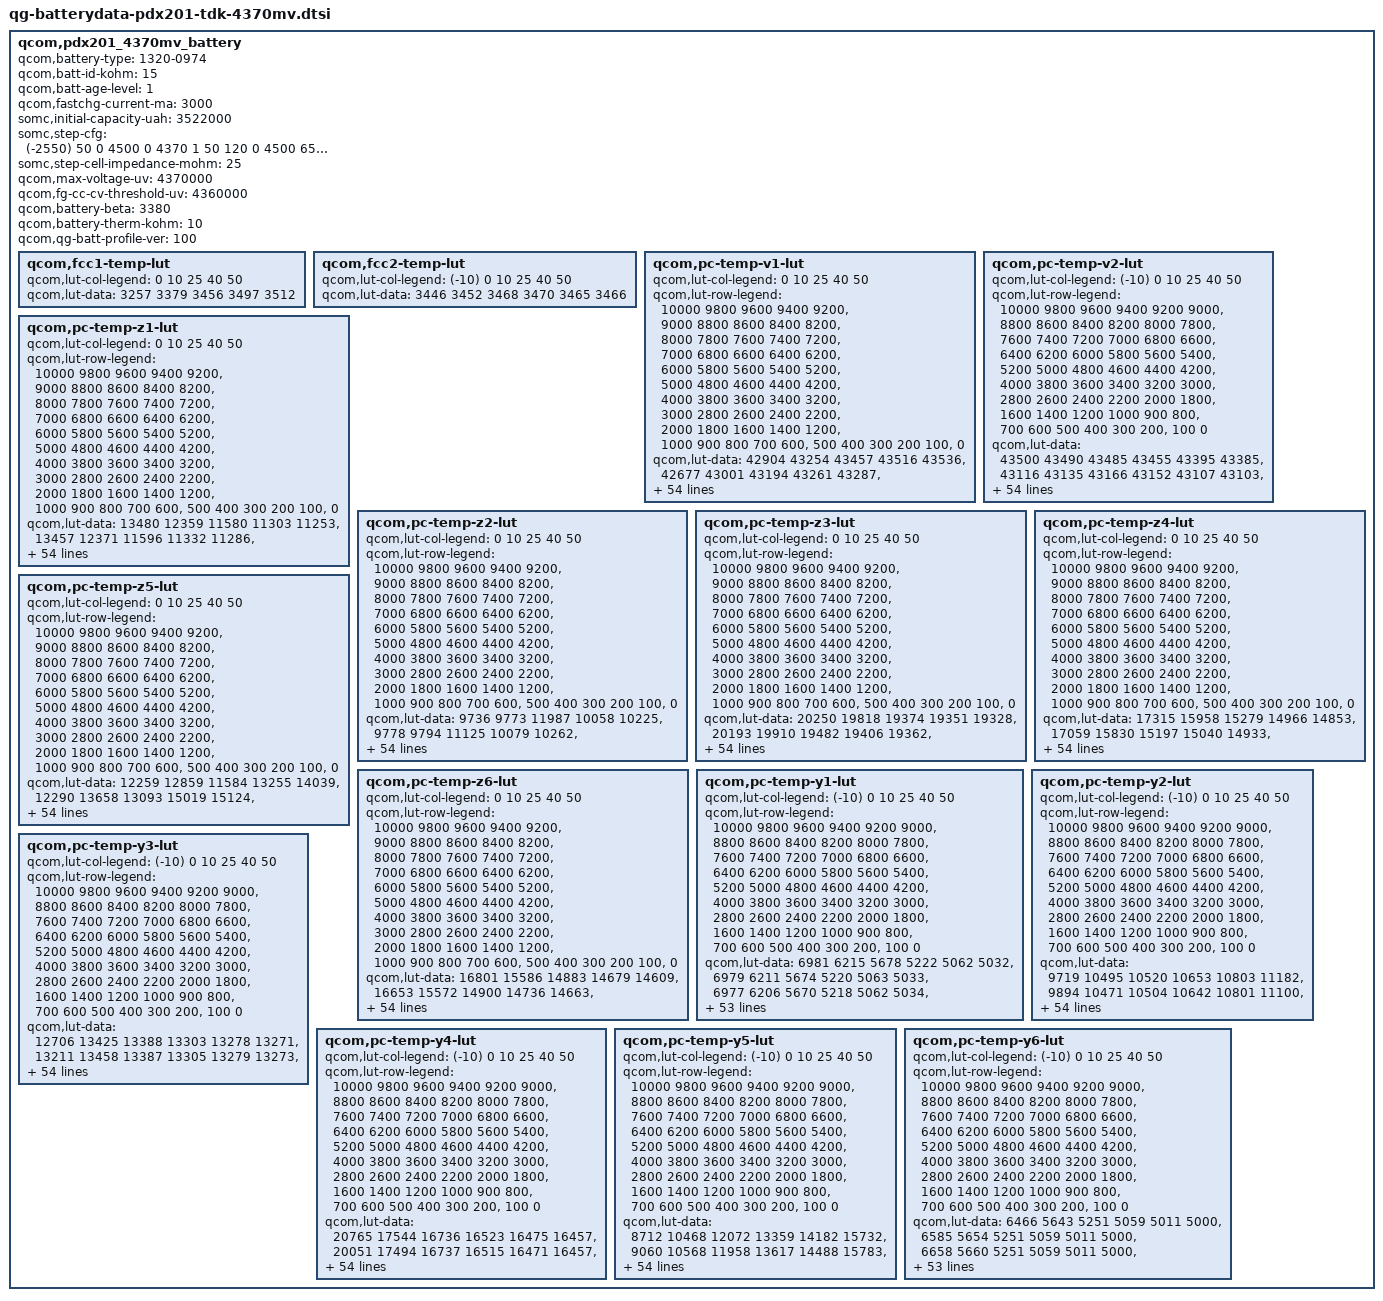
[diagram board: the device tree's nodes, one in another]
// SPDX-License-Identifier: GPL-2.0-only
/*
 * Copyright (c) 2019, The Linux Foundation. All rights reserved.
 */

qcom,pdx201_4370mv_battery {
	/* Added or Modified by SOMC */
	qcom,battery-type = "1320-0974";
	qcom,batt-id-kohm = <15>;
	qcom,batt-age-level = <1>;
	qcom,fastchg-current-ma = <3000>;
	somc,initial-capacity-uah = <3522000>;
	somc,step-cfg = <
		(-2550) 50    0 4500    0 4370 1
		   50  120    0 4500  650 4370 2
		  120  200    0 4100 2050 4370 3
		  120  200 4100 4200 1550 4370 3
		  120  200 4200 4300 1350 4370 3
		  120  200 4300 4500 1000 4370 3
		  200  450    0 4150 3000 4370 3
		  200  450 4150 4200 2400 4370 3
		  200  450 4200 4300 1700 4370 3
		  200  450 4300 4500 1000 4370 3
		  450  550    0 4500 1000 4200 4
		  550 2550    0 4500    0 4200 5
	>;
	somc,step-cell-impedance-mohm = <25>;

	/* Prepared by Qualcomm */
	/* 4209985_SoMC_Amuro2_3471mAh_averaged_MasterSlave_Oct15th2019 */
	qcom,max-voltage-uv = <4370000>;
	qcom,fg-cc-cv-threshold-uv = <4360000>;
	/* qcom,fastchg-current-ma = <1500>; */
	/* qcom,batt-id-kohm = <330>; */
	qcom,battery-beta = <3380>;
	qcom,battery-therm-kohm = <10>;
	/* qcom,battery-type = "4209985_SoMC_Amuro2_3471mAh_averaged_MasterSlave_Oct15th2019"; */
	qcom,qg-batt-profile-ver = <100>;

	qcom,fcc1-temp-lut {
		qcom,lut-col-legend = <0 10 25 40 50>;
		qcom,lut-data = <3257 3379 3456 3497 3512>;
	};

	qcom,fcc2-temp-lut {
		qcom,lut-col-legend = <(-10) 0 10 25 40 50>;
		qcom,lut-data = <3446 3452 3468 3470 3465 3466>;
	};

	qcom,pc-temp-v1-lut {
		qcom,lut-col-legend = <0 10 25 40 50>;
		qcom,lut-row-legend = <10000 9800 9600 9400 9200>,
			<9000 8800 8600 8400 8200>,
			<8000 7800 7600 7400 7200>,
			<7000 6800 6600 6400 6200>,
			<6000 5800 5600 5400 5200>,
			<5000 4800 4600 4400 4200>,
			<4000 3800 3600 3400 3200>,
			<3000 2800 2600 2400 2200>,
			<2000 1800 1600 1400 1200>,
			<1000 900 800 700 600>,
			<500 400 300 200 100>,
			<0>;
		qcom,lut-data = <42904 43254 43457 43516 43536>,
			<42677 43001 43194 43261 43287>,
			<42458 42763 42939 43014 43038>,
			<42249 42536 42696 42775 42796>,
			<42047 42315 42463 42543 42564>,
			<41847 42103 42235 42315 42338>,
			<41641 41895 42011 42087 42114>,
			<41447 41687 41793 41862 41892>,
			<41289 41475 41578 41642 41673>,
			<41164 41289 41365 41423 41454>,
			<41010 41154 41178 41212 41237>,
			<40723 41025 41035 41024 41028>,
			<40349 40810 40889 40855 40826>,
			<40089 40440 40652 40665 40629>,
			<39930 40121 40309 40421 40432>,
			<39804 39959 40059 40181 40242>,
			<39691 39839 39936 40009 40065>,
			<39594 39723 39835 39873 39901>,
			<39496 39618 39710 39732 39741>,
			<39382 39508 39568 39589 39592>,
			<39262 39376 39406 39433 39440>,
			<39146 39227 39196 39227 39250>,
			<39032 39063 38977 38981 39020>,
			<38920 38856 38802 38799 38832>,
			<38810 38664 38648 38677 38699>,
			<38698 38547 38533 38574 38585>,
			<38596 38461 38455 38478 38479>,
			<38505 38395 38392 38389 38381>,
			<38423 38342 38329 38307 38293>,
			<38363 38298 38266 38229 38214>,
			<38320 38257 38209 38160 38143>,
			<38285 38220 38156 38100 38077>,
			<38254 38187 38108 38048 38019>,
			<38227 38157 38067 38000 37966>,
			<38203 38131 38035 37961 37923>,
			<38179 38102 38000 37921 37878>,
			<38157 38075 37966 37876 37818>,
			<38122 38040 37928 37827 37748>,
			<38062 37980 37871 37764 37673>,
			<37983 37891 37784 37680 37598>,
			<37890 37793 37682 37581 37513>,
			<37774 37685 37572 37472 37407>,
			<37641 37560 37446 37346 37281>,
			<37489 37408 37295 37195 37127>,
			<37362 37268 37160 37060 36993>,
			<37279 37189 37075 36975 36913>,
			<37257 37163 37053 36954 36892>,
			<37238 37146 37041 36942 36877>,
			<37212 37130 37022 36923 36857>,
			<37132 37068 36961 36851 36773>,
			<36849 36802 36688 36562 36471>,
			<36406 36363 36261 36130 36038>,
			<35840 35798 35701 35569 35477>,
			<35078 35035 34944 34807 34713>,
			<33876 33848 33780 33634 33539>,
			<30000 30000 30000 30000 30000>;
	};

	qcom,pc-temp-v2-lut {
		qcom,lut-col-legend = <(-10) 0 10 25 40 50>;
		qcom,lut-row-legend = <10000 9800 9600 9400 9200 9000>,
			<8800 8600 8400 8200 8000 7800>,
			<7600 7400 7200 7000 6800 6600>,
			<6400 6200 6000 5800 5600 5400>,
			<5200 5000 4800 4600 4400 4200>,
			<4000 3800 3600 3400 3200 3000>,
			<2800 2600 2400 2200 2000 1800>,
			<1600 1400 1200 1000 900 800>,
			<700 600 500 400 300 200>,
			<100 0>;
		qcom,lut-data = <43500 43490 43485 43455 43395 43385>,
			<43116 43135 43166 43152 43107 43103>,
			<42779 42815 42874 42872 42838 42837>,
			<42501 42538 42612 42616 42587 42588>,
			<42276 42297 42378 42383 42356 42357>,
			<42051 42070 42154 42159 42131 42132>,
			<41765 41846 41933 41936 41906 41907>,
			<41483 41630 41719 41717 41686 41686>,
			<41332 41417 41504 41497 41468 41469>,
			<41260 41203 41285 41274 41252 41255>,
			<41169 41011 41088 41071 41044 41045>,
			<40912 40869 40941 40913 40856 40841>,
			<40515 40739 40802 40764 40674 40642>,
			<40172 40524 40582 40547 40468 40449>,
			<39849 40137 40230 40226 40230 40259>,
			<39598 39791 39925 39966 40019 40078>,
			<39462 39605 39749 39833 39869 39909>,
			<39362 39463 39608 39729 39739 39747>,
			<39229 39313 39449 39591 39591 39584>,
			<39055 39160 39274 39422 39430 39425>,
			<38851 39009 39104 39239 39255 39255>,
			<38568 38858 38938 39029 39042 39045>,
			<38251 38711 38779 38818 38821 38826>,
			<38108 38586 38642 38659 38657 38662>,
			<38057 38484 38523 38537 38533 38536>,
			<38019 38377 38415 38429 38425 38426>,
			<37976 38217 38317 38330 38326 38326>,
			<37936 38039 38228 38241 38236 38235>,
			<37897 37946 38149 38160 38155 38151>,
			<37860 37904 38077 38086 38080 38075>,
			<37823 37871 38009 38018 38013 38006>,
			<37783 37838 37931 37954 37951 37943>,
			<37741 37807 37858 37895 37894 37885>,
			<37701 37772 37805 37837 37832 37821>,
			<37661 37731 37767 37782 37769 37753>,
			<37621 37688 37729 37726 37698 37674>,
			<37579 37645 37686 37662 37611 37571>,
			<37536 37603 37640 37595 37515 37457>,
			<37481 37550 37584 37526 37433 37367>,
			<37407 37484 37518 37457 37365 37297>,
			<37323 37407 37440 37379 37291 37223>,
			<37240 37315 37342 37282 37197 37130>,
			<37154 37204 37227 37167 37084 37020>,
			<37073 37078 37089 37024 36940 36876>,
			<36995 36960 36969 36919 36846 36787>,
			<36919 36884 36905 36877 36811 36753>,
			<36879 36855 36886 36862 36796 36738>,
			<36828 36821 36864 36840 36775 36716>,
			<36759 36770 36831 36802 36731 36675>,
			<36645 36663 36744 36684 36596 36524>,
			<36394 36420 36468 36338 36250 36164>,
			<35969 35983 36001 35863 35766 35671>,
			<35362 35383 35397 35243 35130 35039>,
			<34502 34559 34582 34389 34264 34162>,
			<33256 33381 33402 33070 32960 32838>,
			<29559 29540 29526 29587 29522 29522>;
	};

	qcom,pc-temp-z1-lut {
		qcom,lut-col-legend = <0 10 25 40 50>;
		qcom,lut-row-legend = <10000 9800 9600 9400 9200>,
			<9000 8800 8600 8400 8200>,
			<8000 7800 7600 7400 7200>,
			<7000 6800 6600 6400 6200>,
			<6000 5800 5600 5400 5200>,
			<5000 4800 4600 4400 4200>,
			<4000 3800 3600 3400 3200>,
			<3000 2800 2600 2400 2200>,
			<2000 1800 1600 1400 1200>,
			<1000 900 800 700 600>,
			<500 400 300 200 100>,
			<0>;
		qcom,lut-data = <13480 12359 11580 11303 11253>,
			<13457 12371 11596 11332 11286>,
			<13452 12376 11605 11341 11297>,
			<13471 12378 11605 11345 11303>,
			<13498 12378 11603 11348 11306>,
			<13511 12378 11603 11350 11309>,
			<13510 12377 11604 11351 11309>,
			<13506 12376 11605 11351 11309>,
			<13506 12375 11607 11351 11309>,
			<13500 12376 11609 11352 11309>,
			<13490 12380 11610 11353 11310>,
			<13466 12385 11609 11355 11310>,
			<13433 12381 11609 11357 11311>,
			<13415 12354 11604 11358 11312>,
			<13407 12334 11592 11354 11312>,
			<13401 12333 11586 11350 11313>,
			<13396 12333 11591 11351 11314>,
			<13390 12336 11598 11355 11315>,
			<13386 12348 11604 11358 11316>,
			<13396 12363 11608 11359 11317>,
			<13417 12372 11611 11360 11318>,
			<13426 12380 11614 11361 11319>,
			<13425 12384 11615 11362 11320>,
			<13423 12387 11618 11363 11321>,
			<13424 12389 11621 11364 11322>,
			<13426 12393 11624 11366 11324>,
			<13428 12398 11628 11369 11326>,
			<13430 12403 11632 11372 11328>,
			<13432 12409 11636 11375 11330>,
			<13434 12415 11639 11377 11332>,
			<13437 12421 11643 11379 11334>,
			<13439 12431 11646 11381 11336>,
			<13444 12437 11649 11383 11337>,
			<13451 12437 11652 11384 11338>,
			<13457 12436 11655 11386 11339>,
			<13460 12439 11659 11387 11340>,
			<13462 12445 11662 11389 11341>,
			<13467 12451 11665 11390 11342>,
			<13479 12459 11668 11391 11342>,
			<13495 12468 11670 11391 11343>,
			<13509 12471 11672 11392 11343>,
			<13523 12468 11674 11393 11344>,
			<13527 12466 11676 11394 11345>,
			<13530 12471 11678 11395 11345>,
			<13467 12471 11682 11396 11346>,
			<13436 12466 11682 11397 11346>,
			<13443 12461 11682 11396 11346>,
			<13449 12456 11682 11395 11346>,
			<13449 12469 11682 11396 11346>,
			<13453 12459 11684 11396 11346>,
			<13451 12477 11691 11398 11348>,
			<13469 12488 11701 11405 11352>,
			<13503 12522 11718 11412 11359>,
			<13522 12561 11743 11425 11368>,
			<13522 12561 11743 11425 11368>,
			<13522 12561 11743 11425 11368>;
	};

	qcom,pc-temp-z2-lut {
		qcom,lut-col-legend = <0 10 25 40 50>;
		qcom,lut-row-legend = <10000 9800 9600 9400 9200>,
			<9000 8800 8600 8400 8200>,
			<8000 7800 7600 7400 7200>,
			<7000 6800 6600 6400 6200>,
			<6000 5800 5600 5400 5200>,
			<5000 4800 4600 4400 4200>,
			<4000 3800 3600 3400 3200>,
			<3000 2800 2600 2400 2200>,
			<2000 1800 1600 1400 1200>,
			<1000 900 800 700 600>,
			<500 400 300 200 100>,
			<0>;
		qcom,lut-data = <9736 9773 11987 10058 10225>,
			<9778 9794 11125 10079 10262>,
			<9806 9797 10550 10278 10486>,
			<9821 9798 10353 10384 10664>,
			<9832 9799 10304 10361 10654>,
			<9838 9809 10301 10333 10616>,
			<9841 9821 10180 10335 10550>,
			<9843 9826 10041 10356 10390>,
			<9842 9828 10113 10364 10287>,
			<9835 9831 10377 10258 10297>,
			<9827 9856 10503 10133 10319>,
			<9818 9888 10478 10125 10340>,
			<9809 9890 10447 10140 10366>,
			<9806 9866 10466 10154 10379>,
			<9807 9849 10548 10165 10378>,
			<9809 9858 10586 10177 10378>,
			<9812 9882 10368 10196 10383>,
			<9817 9907 10095 10221 10407>,
			<9820 9934 10075 10233 10425>,
			<9818 9961 10130 10233 10430>,
			<9815 9979 10174 10233 10434>,
			<9814 9994 10198 10286 10432>,
			<9820 10010 10215 10411 10427>,
			<9828 10035 10213 10450 10425>,
			<9837 10054 10202 10352 10456>,
			<9848 10052 10195 10259 10499>,
			<9857 10041 10207 10282 10516>,
			<9865 10033 10225 10350 10514>,
			<9872 10030 10237 10376 10494>,
			<9874 10029 10250 10374 10395>,
			<9873 10030 10256 10370 10300>,
			<9873 10035 10245 10364 10296>,
			<9874 10041 10231 10358 10306>,
			<9876 10045 10230 10363 10321>,
			<9880 10049 10238 10394 10363>,
			<9885 10053 10248 10433 10429>,
			<9891 10057 10262 10466 10551>,
			<9899 10062 10280 10501 10718>,
			<9910 10072 10300 10532 10759>,
			<9923 10086 10324 10571 10679>,
			<9936 10095 10338 10594 10609>,
			<9950 10099 10342 10581 10604>,
			<9972 10105 10346 10559 10603>,
			<10015 10124 10352 10524 10603>,
			<10239 10245 10405 10529 10627>,
			<10239 10286 10436 10542 10650>,
			<10232 10277 10411 10515 10634>,
			<10229 10273 10408 10524 10644>,
			<10239 10285 10411 10536 10694>,
			<10267 10314 10456 10670 10767>,
			<10273 10335 10478 10584 10506>,
			<10212 10283 10417 10496 10390>,
			<10122 10245 10365 10417 10363>,
			<9934 10194 10290 10353 10300>,
			<9934 10194 10290 10353 10300>,
			<9934 10194 10290 10353 10300>;
	};

	qcom,pc-temp-z3-lut {
		qcom,lut-col-legend = <0 10 25 40 50>;
		qcom,lut-row-legend = <10000 9800 9600 9400 9200>,
			<9000 8800 8600 8400 8200>,
			<8000 7800 7600 7400 7200>,
			<7000 6800 6600 6400 6200>,
			<6000 5800 5600 5400 5200>,
			<5000 4800 4600 4400 4200>,
			<4000 3800 3600 3400 3200>,
			<3000 2800 2600 2400 2200>,
			<2000 1800 1600 1400 1200>,
			<1000 900 800 700 600>,
			<500 400 300 200 100>,
			<0>;
		qcom,lut-data = <20250 19818 19374 19351 19328>,
			<20193 19910 19482 19406 19362>,
			<20131 19914 19556 19430 19395>,
			<20054 19907 19583 19438 19413>,
			<19974 19898 19601 19439 19411>,
			<19935 19877 19607 19439 19407>,
			<19923 19854 19579 19438 19400>,
			<19914 19841 19547 19430 19383>,
			<19902 19830 19551 19419 19369>,
			<19887 19826 19575 19404 19366>,
			<19879 19844 19587 19388 19364>,
			<19900 19870 19573 19377 19359>,
			<19943 19866 19555 19368 19351>,
			<19957 19814 19550 19366 19345>,
			<19931 19757 19550 19367 19342>,
			<19902 19714 19546 19369 19340>,
			<19895 19677 19485 19368 19336>,
			<19893 19656 19412 19362 19331>,
			<19892 19642 19408 19360 19327>,
			<19912 19635 19428 19361 19327>,
			<19949 19642 19451 19362 19326>,
			<19966 19665 19485 19370 19329>,
			<19970 19692 19515 19387 19338>,
			<19973 19731 19517 19392 19343>,
			<19980 19763 19509 19374 19333>,
			<19995 19763 19499 19356 19321>,
			<20005 19751 19485 19358 19330>,
			<20006 19738 19472 19368 19361>,
			<20006 19722 19472 19380 19375>,
			<20003 19707 19482 19401 19372>,
			<19989 19698 19491 19416 19368>,
			<19971 19691 19503 19414 19365>,
			<19959 19687 19513 19409 19363>,
			<19951 19684 19513 19403 19360>,
			<19942 19681 19505 19396 19354>,
			<19932 19679 19497 19390 19349>,
			<19920 19676 19492 19388 19352>,
			<19911 19674 19488 19387 19359>,
			<19905 19672 19483 19385 19361>,
			<19898 19670 19478 19382 19357>,
			<19885 19667 19475 19378 19352>,
			<19865 19659 19474 19376 19346>,
			<19842 19648 19473 19374 19341>,
			<19808 19628 19462 19363 19343>,
			<19673 19576 19438 19356 19339>,
			<19668 19546 19427 19354 19329>,
			<19663 19547 19427 19353 19328>,
			<19655 19542 19412 19342 19326>,
			<19642 19527 19414 19340 19322>,
			<19629 19525 19404 19333 19323>,
			<19631 19515 19395 19339 19345>,
			<19626 19519 19393 19346 19348>,
			<19588 19511 19396 19355 19350>,
			<19501 19478 19384 19358 19356>,
			<19501 19478 19384 19358 19356>,
			<19501 19478 19384 19358 19356>;
	};

	qcom,pc-temp-z4-lut {
		qcom,lut-col-legend = <0 10 25 40 50>;
		qcom,lut-row-legend = <10000 9800 9600 9400 9200>,
			<9000 8800 8600 8400 8200>,
			<8000 7800 7600 7400 7200>,
			<7000 6800 6600 6400 6200>,
			<6000 5800 5600 5400 5200>,
			<5000 4800 4600 4400 4200>,
			<4000 3800 3600 3400 3200>,
			<3000 2800 2600 2400 2200>,
			<2000 1800 1600 1400 1200>,
			<1000 900 800 700 600>,
			<500 400 300 200 100>,
			<0>;
		qcom,lut-data = <17315 15958 15279 14966 14853>,
			<17059 15830 15197 15040 14933>,
			<16831 15669 15119 14980 14897>,
			<16630 15485 15039 14922 14854>,
			<16449 15344 14949 14882 14818>,
			<16287 15247 14900 14849 14787>,
			<16144 15169 14882 14824 14781>,
			<16011 15109 14864 14802 14781>,
			<15878 15063 14833 14795 14781>,
			<15743 15006 14778 14795 14775>,
			<15636 14882 14737 14796 14762>,
			<15569 14754 14710 14792 14752>,
			<15517 14748 14692 14776 14745>,
			<15457 14842 14692 14764 14737>,
			<15383 14911 14698 14758 14728>,
			<15309 14909 14708 14752 14717>,
			<15248 14902 14747 14739 14708>,
			<15196 14894 14791 14718 14698>,
			<15148 14883 14787 14703 14691>,
			<15096 14872 14754 14695 14685>,
			<15048 14859 14736 14690 14681>,
			<15026 14846 14760 14719 14701>,
			<15015 14843 14802 14802 14778>,
			<15010 14882 14842 14850 14827>,
			<15010 14929 14888 14869 14844>,
			<15011 14945 14909 14879 14853>,
			<15013 14953 14904 14870 14839>,
			<15021 14956 14893 14842 14788>,
			<15034 14954 14877 14811 14753>,
			<15040 14949 14849 14770 14737>,
			<15043 14942 14822 14737 14724>,
			<15044 14931 14794 14722 14711>,
			<15043 14920 14771 14713 14698>,
			<15037 14909 14764 14709 14693>,
			<15029 14899 14762 14707 14692>,
			<15021 14893 14761 14707 14691>,
			<15012 14888 14763 14711 14700>,
			<15005 14885 14768 14722 14721>,
			<14999 14890 14777 14733 14727>,
			<14995 14902 14797 14745 14727>,
			<14993 14905 14808 14753 14727>,
			<14993 14899 14800 14748 14724>,
			<14986 14889 14792 14742 14719>,
			<14953 14878 14794 14754 14722>,
			<14867 14821 14776 14748 14720>,
			<14852 14797 14745 14721 14708>,
			<14846 14787 14735 14707 14692>,
			<14839 14783 14731 14695 14670>,
			<14830 14780 14715 14681 14656>,
			<14829 14774 14728 14698 14671>,
			<14843 14799 14764 14718 14667>,
			<14865 14800 14768 14711 14665>,
			<14900 14804 14764 14701 14663>,
			<14985 14824 14771 14694 14655>,
			<14985 14824 14771 14694 14655>,
			<14985 14824 14771 14694 14655>;
	};

	qcom,pc-temp-z5-lut {
		qcom,lut-col-legend = <0 10 25 40 50>;
		qcom,lut-row-legend = <10000 9800 9600 9400 9200>,
			<9000 8800 8600 8400 8200>,
			<8000 7800 7600 7400 7200>,
			<7000 6800 6600 6400 6200>,
			<6000 5800 5600 5400 5200>,
			<5000 4800 4600 4400 4200>,
			<4000 3800 3600 3400 3200>,
			<3000 2800 2600 2400 2200>,
			<2000 1800 1600 1400 1200>,
			<1000 900 800 700 600>,
			<500 400 300 200 100>,
			<0>;
		qcom,lut-data = <12259 12859 11584 13255 14039>,
			<12290 13658 13093 15019 15124>,
			<12314 14011 14431 15808 16926>,
			<12329 14225 15645 16253 18176>,
			<12349 14396 16820 16491 18562>,
			<12379 14524 17405 16675 18791>,
			<12478 14657 17095 16953 18643>,
			<12599 14870 16744 17310 17405>,
			<12668 15205 17650 17439 16524>,
			<12708 15789 20126 16673 16683>,
			<12767 19308 22234 15721 16949>,
			<13041 23872 23704 15512 16946>,
			<13485 24148 24798 15433 16649>,
			<13664 20720 25192 15419 16462>,
			<13672 17644 24965 15670 16707>,
			<13675 16476 24122 16119 17104>,
			<13740 15690 19588 16640 17269>,
			<13960 15537 14496 17349 17342>,
			<14307 15743 14192 18167 17463>,
			<15192 16134 15890 19033 18058>,
			<16644 17119 18636 20220 19015>,
			<17856 19388 28981 23194 20082>,
			<18715 22650 40479 28069 21476>,
			<19612 30174 40170 29325 21966>,
			<21002 36946 32397 23069 18633>,
			<23048 36303 25644 16766 14766>,
			<24654 31552 21402 15870 14868>,
			<25544 27375 18462 15492 16367>,
			<26213 24572 18016 15576 17404>,
			<26301 22443 18154 17717 17878>,
			<25124 21584 18503 20446 18408>,
			<23659 21098 20734 22351 19598>,
			<22982 20900 23672 24028 21575>,
			<22547 20990 24529 25104 22955>,
			<22249 21205 24851 25903 23720>,
			<22025 21447 24963 26309 24391>,
			<21859 21773 24729 25971 25312>,
			<21873 22087 24206 25036 26268>,
			<22573 22333 23324 23832 26239>,
			<23305 22545 21574 21362 23198>,
			<23207 22574 20601 19417 20000>,
			<22661 22059 20641 19026 18784>,
			<22727 21514 20675 18696 17981>,
			<23595 21096 19244 16773 17385>,
			<24541 22814 19204 16424 16634>,
			<24783 22104 19982 17292 16145>,
			<24052 22565 20065 17800 16750>,
			<23399 22238 18542 17114 18163>,
			<22815 20914 19806 18056 19559>,
			<22186 21464 18377 16195 17232>,
			<22385 19108 15692 14669 18022>,
			<18785 18284 15136 14945 18460>,
			<15876 16975 15029 15595 18532>,
			<13323 14722 14127 15877 20298>,
			<13323 14722 14127 15877 20298>,
			<13323 14722 14127 15877 20298>;
	};

	qcom,pc-temp-z6-lut {
		qcom,lut-col-legend = <0 10 25 40 50>;
		qcom,lut-row-legend = <10000 9800 9600 9400 9200>,
			<9000 8800 8600 8400 8200>,
			<8000 7800 7600 7400 7200>,
			<7000 6800 6600 6400 6200>,
			<6000 5800 5600 5400 5200>,
			<5000 4800 4600 4400 4200>,
			<4000 3800 3600 3400 3200>,
			<3000 2800 2600 2400 2200>,
			<2000 1800 1600 1400 1200>,
			<1000 900 800 700 600>,
			<500 400 300 200 100>,
			<0>;
		qcom,lut-data = <16801 15586 14883 14679 14609>,
			<16653 15572 14900 14736 14663>,
			<16516 15525 14906 14727 14664>,
			<16384 15433 14899 14716 14663>,
			<16261 15356 14870 14703 14655>,
			<16165 15301 14842 14687 14638>,
			<16094 15255 14816 14674 14627>,
			<16031 15221 14794 14662 14618>,
			<15965 15195 14782 14651 14611>,
			<15895 15166 14774 14643 14605>,
			<15843 15120 14763 14635 14599>,
			<15818 15076 14743 14626 14592>,
			<15800 15069 14725 14615 14585>,
			<15774 15072 14723 14609 14578>,
			<15726 15075 14723 14606 14572>,
			<15675 15061 14722 14604 14566>,
			<15645 15034 14706 14597 14560>,
			<15622 15018 14687 14584 14552>,
			<15610 15008 14683 14577 14547>,
			<15610 15002 14683 14574 14544>,
			<15609 15004 14683 14572 14542>,
			<15609 15011 14707 14590 14552>,
			<15609 15022 14745 14637 14592>,
			<15610 15061 14765 14654 14613>,
			<15613 15099 14779 14653 14614>,
			<15621 15103 14784 14651 14614>,
			<15630 15101 14777 14648 14613>,
			<15636 15100 14766 14642 14608>,
			<15641 15093 14758 14636 14601>,
			<15643 15083 14752 14630 14594>,
			<15637 15075 14746 14623 14585>,
			<15629 15069 14741 14617 14578>,
			<15624 15063 14737 14610 14572>,
			<15620 15057 14732 14604 14567>,
			<15615 15053 14727 14599 14562>,
			<15608 15050 14724 14596 14559>,
			<15599 15048 14723 14597 14564>,
			<15594 15047 14722 14601 14577>,
			<15591 15049 14724 14604 14581>,
			<15588 15054 14730 14607 14579>,
			<15583 15056 14734 14608 14575>,
			<15573 15050 14731 14606 14571>,
			<15558 15041 14726 14602 14567>,
			<15525 15027 14722 14601 14569>,
			<15423 14979 14702 14595 14566>,
			<15412 14952 14683 14582 14555>,
			<15406 14949 14678 14576 14548>,
			<15399 14943 14669 14565 14537>,
			<15391 14935 14663 14557 14528>,
			<15389 14934 14664 14561 14535>,
			<15406 14944 14676 14574 14546>,
			<15423 14952 14679 14576 14549>,
			<15439 14960 14683 14578 14550>,
			<15462 14970 14686 14579 14552>,
			<15462 14970 14686 14579 14552>,
			<15462 14970 14686 14579 14552>;
	};

	qcom,pc-temp-y1-lut {
		qcom,lut-col-legend = <(-10) 0 10 25 40 50>;
		qcom,lut-row-legend = <10000 9800 9600 9400 9200 9000>,
			<8800 8600 8400 8200 8000 7800>,
			<7600 7400 7200 7000 6800 6600>,
			<6400 6200 6000 5800 5600 5400>,
			<5200 5000 4800 4600 4400 4200>,
			<4000 3800 3600 3400 3200 3000>,
			<2800 2600 2400 2200 2000 1800>,
			<1600 1400 1200 1000 900 800>,
			<700 600 500 400 300 200>,
			<100 0>;
		qcom,lut-data = <6981 6215 5678 5222 5062 5032>,
			<6979 6211 5674 5220 5063 5033>,
			<6977 6206 5670 5218 5062 5034>,
			<6974 6201 5665 5215 5062 5035>,
			<6971 6196 5661 5213 5061 5035>,
			<6970 6193 5657 5212 5061 5035>,
			<6970 6190 5653 5210 5060 5035>,
			<6971 6188 5649 5209 5059 5035>,
			<6970 6187 5649 5208 5058 5034>,
			<6967 6187 5649 5206 5058 5034>,
			<6964 6187 5648 5205 5057 5034>,
			<6958 6183 5642 5203 5057 5034>,
			<6950 6175 5633 5203 5057 5035>,
			<6949 6175 5631 5203 5058 5035>,
			<6952 6188 5633 5205 5059 5035>,
			<6956 6198 5635 5207 5060 5036>,
			<6964 6198 5640 5208 5060 5035>,
			<6974 6197 5645 5210 5060 5035>,
			<6976 6198 5646 5210 5060 5035>,
			<6968 6204 5643 5210 5061 5035>,
			<6961 6208 5642 5210 5062 5035>,
			<6964 6209 5646 5212 5063 5036>,
			<6970 6209 5652 5214 5063 5038>,
			<6971 6209 5654 5216 5063 5038>,
			<6961 6210 5652 5218 5064 5038>,
			<6952 6212 5652 5220 5065 5038>,
			<6956 6220 5656 5222 5066 5039>,
			<6966 6233 5660 5224 5067 5041>,
			<6967 6238 5665 5226 5069 5042>,
			<6950 6239 5670 5229 5070 5042>,
			<6936 6238 5675 5233 5072 5043>,
			<6944 6237 5679 5237 5074 5045>,
			<6968 6234 5682 5241 5076 5047>,
			<6981 6232 5687 5245 5078 5048>,
			<6986 6230 5693 5250 5079 5049>,
			<6987 6229 5700 5254 5081 5050>,
			<6970 6231 5707 5256 5082 5051>,
			<6931 6236 5715 5259 5084 5051>,
			<6917 6236 5717 5260 5084 5052>,
			<6931 6230 5718 5262 5084 5052>,
			<6946 6224 5719 5263 5085 5052>,
			<6936 6230 5724 5265 5085 5052>,
			<6910 6240 5729 5267 5085 5052>,
			<6904 6240 5729 5271 5086 5053>,
			<6903 6239 5732 5275 5087 5054>,
			<6927 6235 5728 5272 5087 5054>,
			<6948 6239 5725 5273 5087 5054>,
			<6962 6251 5733 5275 5088 5055>,
			<6940 6251 5730 5277 5088 5054>,
			<6947 6245 5739 5278 5088 5055>,
			<6973 6245 5752 5282 5090 5057>,
			<6963 6265 5760 5291 5094 5060>,
			<7023 6288 5771 5306 5102 5064>,
			<7101 6313 5804 5323 5109 5070>,
			<7101 6313 5804 5323 5109 5070>,
			<7101 6313 5804 5323 5109 5070>;
	};

	qcom,pc-temp-y2-lut {
		qcom,lut-col-legend = <(-10) 0 10 25 40 50>;
		qcom,lut-row-legend = <10000 9800 9600 9400 9200 9000>,
			<8800 8600 8400 8200 8000 7800>,
			<7600 7400 7200 7000 6800 6600>,
			<6400 6200 6000 5800 5600 5400>,
			<5200 5000 4800 4600 4400 4200>,
			<4000 3800 3600 3400 3200 3000>,
			<2800 2600 2400 2200 2000 1800>,
			<1600 1400 1200 1000 900 800>,
			<700 600 500 400 300 200>,
			<100 0>;
		qcom,lut-data = <9719 10495 10520 10653 10803 11182>,
			<9894 10471 10504 10642 10801 11100>,
			<10074 10446 10490 10631 10798 11035>,
			<10238 10420 10476 10621 10795 10988>,
			<10363 10395 10463 10612 10792 10957>,
			<10426 10372 10453 10607 10791 10944>,
			<10424 10344 10443 10605 10783 10956>,
			<10399 10319 10435 10605 10770 10980>,
			<10385 10320 10430 10606 10768 10979>,
			<10344 10360 10426 10609 10768 10963>,
			<10320 10411 10425 10613 10768 10953>,
			<10441 10475 10429 10623 10757 10976>,
			<10644 10539 10439 10641 10742 11011>,
			<10696 10550 10463 10662 10745 11018>,
			<10694 10528 10529 10694 10780 11007>,
			<10687 10511 10582 10729 10813 10997>,
			<10617 10549 10600 10773 10850 10994>,
			<10471 10627 10612 10814 10907 10995>,
			<10368 10675 10630 10824 10970 11012>,
			<10302 10703 10655 10826 11080 11077>,
			<10221 10729 10684 10828 11146 11128>,
			<10023 10766 10721 10841 11081 11138>,
			<9753 10804 10764 10866 10975 11140>,
			<9669 10808 10803 10895 10958 11139>,
			<9661 10771 10840 10938 10992 11136>,
			<9657 10739 10873 10983 11029 11135>,
			<9656 10741 10909 11029 11052 11158>,
			<9655 10752 10938 11073 11076 11203>,
			<9654 10740 10943 11103 11104 11243>,
			<9654 10658 10937 11122 11164 11286>,
			<9653 10582 10932 11146 11229 11313>,
			<9653 10568 10933 11205 11289 11315>,
			<9653 10561 10934 11271 11349 11313>,
			<9653 10515 10922 11279 11408 11334>,
			<9653 10158 10851 11256 11481 11428>,
			<9653 9815 10773 11237 11521 11526>,
			<9653 9738 10715 11214 11502 11602>,
			<9653 9694 10661 11179 11464 11663>,
			<9653 9678 10618 11165 11442 11670>,
			<9653 9672 10584 11153 11427 11641>,
			<9653 9668 10551 11140 11419 11617>,
			<9653 9665 10516 11126 11429 11603>,
			<9653 9662 10482 11109 11441 11597>,
			<9653 9659 10450 11060 11398 11622>,
			<9653 9658 10412 10998 11328 11571>,
			<9652 9658 10452 11023 11267 11377>,
			<9652 9658 10438 11031 11314 11382>,
			<9652 9657 10412 11029 11296 11255>,
			<9652 9656 10402 10992 11266 11234>,
			<9652 9655 10386 10983 11236 11188>,
			<9652 9655 10356 10956 11189 11121>,
			<9651 9654 10313 10869 11086 11055>,
			<9650 9653 10266 10809 11013 10962>,
			<9649 9651 10224 10737 10913 10872>,
			<9649 9651 10224 10737 10913 10872>,
			<9649 9651 10224 10737 10913 10872>;
	};

	qcom,pc-temp-y3-lut {
		qcom,lut-col-legend = <(-10) 0 10 25 40 50>;
		qcom,lut-row-legend = <10000 9800 9600 9400 9200 9000>,
			<8800 8600 8400 8200 8000 7800>,
			<7600 7400 7200 7000 6800 6600>,
			<6400 6200 6000 5800 5600 5400>,
			<5200 5000 4800 4600 4400 4200>,
			<4000 3800 3600 3400 3200 3000>,
			<2800 2600 2400 2200 2000 1800>,
			<1600 1400 1200 1000 900 800>,
			<700 600 500 400 300 200>,
			<100 0>;
		qcom,lut-data = <12706 13425 13388 13303 13278 13271>,
			<13211 13458 13387 13305 13279 13273>,
			<13541 13485 13386 13306 13280 13274>,
			<13732 13506 13386 13307 13281 13275>,
			<13820 13520 13387 13308 13281 13276>,
			<13842 13525 13388 13308 13282 13276>,
			<13718 13518 13390 13308 13282 13277>,
			<13509 13506 13392 13308 13283 13278>,
			<13469 13504 13395 13307 13282 13278>,
			<13519 13509 13399 13305 13282 13278>,
			<13581 13517 13403 13304 13282 13278>,
			<13647 13531 13410 13309 13284 13278>,
			<13711 13547 13417 13316 13287 13277>,
			<13711 13547 13416 13317 13287 13277>,
			<13604 13519 13405 13314 13286 13280>,
			<13505 13490 13397 13312 13286 13282>,
			<13470 13474 13400 13317 13287 13282>,
			<13448 13461 13405 13323 13290 13282>,
			<13444 13451 13404 13325 13292 13282>,
			<13447 13444 13393 13324 13295 13284>,
			<13451 13436 13380 13324 13296 13285>,
			<13453 13427 13368 13317 13292 13282>,
			<13455 13416 13358 13307 13284 13277>,
			<13467 13404 13352 13303 13281 13275>,
			<13558 13386 13349 13301 13281 13275>,
			<13683 13373 13346 13300 13280 13275>,
			<13800 13371 13345 13299 13280 13275>,
			<13925 13371 13344 13298 13280 13275>,
			<14028 13373 13343 13298 13281 13275>,
			<14110 13389 13339 13301 13282 13276>,
			<14182 13405 13337 13302 13283 13277>,
			<14247 13411 13337 13302 13284 13277>,
			<14307 13416 13339 13300 13285 13277>,
			<14366 13417 13342 13300 13285 13277>,
			<14422 13410 13349 13300 13284 13277>,
			<14479 13403 13357 13300 13283 13277>,
			<14540 13410 13364 13300 13281 13275>,
			<14604 13429 13371 13300 13279 13272>,
			<14665 13450 13376 13301 13279 13272>,
			<14721 13473 13379 13300 13279 13272>,
			<14779 13503 13382 13300 13279 13272>,
			<14843 13540 13384 13301 13279 13273>,
			<14915 13591 13386 13303 13279 13275>,
			<15001 13665 13389 13304 13280 13273>,
			<15100 13763 13394 13305 13281 13274>,
			<15107 13775 13381 13305 13282 13276>,
			<14990 13749 13387 13306 13284 13276>,
			<15131 13831 13393 13307 13286 13281>,
			<15281 13924 13405 13313 13290 13287>,
			<15449 14030 13415 13316 13291 13286>,
			<15610 14147 13417 13310 13291 13282>,
			<15889 14316 13426 13322 13293 13283>,
			<16502 14646 13449 13330 13294 13288>,
			<17206 15116 13484 13337 13299 13291>,
			<17206 15116 13484 13337 13299 13291>,
			<17206 15116 13484 13337 13299 13291>;
	};

	qcom,pc-temp-y4-lut {
		qcom,lut-col-legend = <(-10) 0 10 25 40 50>;
		qcom,lut-row-legend = <10000 9800 9600 9400 9200 9000>,
			<8800 8600 8400 8200 8000 7800>,
			<7600 7400 7200 7000 6800 6600>,
			<6400 6200 6000 5800 5600 5400>,
			<5200 5000 4800 4600 4400 4200>,
			<4000 3800 3600 3400 3200 3000>,
			<2800 2600 2400 2200 2000 1800>,
			<1600 1400 1200 1000 900 800>,
			<700 600 500 400 300 200>,
			<100 0>;
		qcom,lut-data = <20765 17544 16736 16523 16475 16457>,
			<20051 17494 16737 16515 16471 16457>,
			<19572 17454 16739 16511 16469 16457>,
			<19284 17425 16741 16511 16469 16457>,
			<19143 17407 16743 16513 16470 16457>,
			<19104 17400 16745 16517 16472 16457>,
			<19272 17409 16746 16523 16476 16459>,
			<19561 17426 16749 16532 16482 16462>,
			<19650 17441 16752 16543 16488 16466>,
			<19671 17451 16757 16556 16495 16471>,
			<19680 17468 16765 16571 16504 16478>,
			<19313 17552 16817 16595 16517 16486>,
			<18630 17674 16888 16619 16532 16495>,
			<18389 17663 16895 16623 16541 16501>,
			<18323 17406 16859 16622 16545 16506>,
			<18295 17215 16835 16621 16551 16513>,
			<18307 17252 16846 16652 16562 16523>,
			<18331 17323 16863 16701 16577 16537>,
			<18316 17337 16859 16710 16594 16554>,
			<18113 17302 16809 16707 16620 16575>,
			<17831 17257 16760 16701 16634 16587>,
			<17495 17215 16729 16639 16587 16552>,
			<17131 17173 16705 16547 16508 16493>,
			<17038 17149 16700 16525 16484 16473>,
			<17071 17138 16699 16521 16477 16467>,
			<17107 17122 16699 16520 16474 16464>,
			<17122 16989 16703 16524 16477 16466>,
			<17134 16751 16712 16534 16484 16471>,
			<17147 16686 16718 16543 16491 16477>,
			<17172 16722 16724 16551 16500 16485>,
			<17192 16771 16727 16560 16511 16495>,
			<17197 16816 16695 16575 16526 16508>,
			<17200 16865 16644 16589 16541 16522>,
			<17206 16923 16637 16591 16544 16525>,
			<17222 16999 16666 16587 16544 16522>,
			<17236 17067 16696 16583 16543 16517>,
			<17239 17109 16718 16572 16527 16503>,
			<17241 17141 16737 16560 16501 16483>,
			<17240 17156 16751 16558 16496 16479>,
			<17231 17165 16761 16560 16502 16483>,
			<17219 17170 16771 16562 16506 16486>,
			<17209 17172 16780 16562 16506 16484>,
			<17200 17175 16790 16562 16504 16481>,
			<17213 17159 16803 16563 16498 16478>,
			<17254 17141 16806 16561 16497 16478>,
			<17283 17125 16750 16553 16504 16486>,
			<17260 17130 16770 16566 16512 16494>,
			<17311 17179 16805 16587 16519 16496>,
			<17363 17255 16854 16607 16528 16509>,
			<17382 17323 16910 16607 16522 16495>,
			<17374 17326 16886 16578 16500 16478>,
			<17389 17320 16888 16602 16508 16484>,
			<17667 17349 16943 16641 16527 16508>,
			<18232 17553 17037 16732 16600 16567>,
			<18232 17553 17037 16732 16600 16567>,
			<18232 17553 17037 16732 16600 16567>;
	};

	qcom,pc-temp-y5-lut {
		qcom,lut-col-legend = <(-10) 0 10 25 40 50>;
		qcom,lut-row-legend = <10000 9800 9600 9400 9200 9000>,
			<8800 8600 8400 8200 8000 7800>,
			<7600 7400 7200 7000 6800 6600>,
			<6400 6200 6000 5800 5600 5400>,
			<5200 5000 4800 4600 4400 4200>,
			<4000 3800 3600 3400 3200 3000>,
			<2800 2600 2400 2200 2000 1800>,
			<1600 1400 1200 1000 900 800>,
			<700 600 500 400 300 200>,
			<100 0>;
		qcom,lut-data = <8712 10468 12072 13359 14182 15732>,
			<9060 10568 11958 13617 14488 15783>,
			<10123 10736 11901 13719 14617 15806>,
			<10841 10924 11885 13704 14613 15806>,
			<11249 11082 11894 13607 14518 15787>,
			<11383 11160 11910 13467 14373 15751>,
			<11044 11176 11945 13243 14115 15576>,
			<10478 11185 12010 12936 13749 15240>,
			<10423 11144 12114 12611 13377 14878>,
			<10980 10888 12332 12214 12934 14434>,
			<11755 10706 12461 12011 12705 13979>,
			<12872 11475 12425 12121 12755 13461>,
			<14098 12823 12369 12301 12836 13009>,
			<14217 13182 12443 12352 12814 12999>,
			<13081 13217 12972 12345 12603 13380>,
			<12200 13231 13602 12352 12460 13635>,
			<12525 12989 14276 12554 12572 13429>,
			<13379 12546 14891 13005 12855 13097>,
			<14322 12468 14984 13767 13339 13104>,
			<15639 12749 14871 15333 14414 13595>,
			<16490 13083 14694 16247 15134 14199>,
			<15009 13290 14204 15754 15210 14839>,
			<11907 13486 13584 14878 15216 15481>,
			<10951 13863 13447 14401 15158 15804>,
			<10932 14786 13452 14059 15035 16013>,
			<10925 15449 13480 13848 14892 16043>,
			<10970 15225 13631 13688 14622 15670>,
			<11074 14657 13957 13539 14299 15100>,
			<11129 14215 14499 13626 14289 14819>,
			<11181 13873 15638 14136 14650 14798>,
			<11230 13586 16507 14614 15006 14835>,
			<11268 13394 16830 14843 15229 14811>,
			<11332 13238 17033 15061 15442 14813>,
			<11394 12939 16988 15515 15663 15024>,
			<11448 12140 16498 16541 16256 15607>,
			<11510 11493 15961 17146 16644 15979>,
			<11653 11411 15599 17004 16526 15738>,
			<11887 11376 15262 16702 16233 15228>,
			<11965 11369 14894 16335 15848 14788>,
			<11824 11385 14496 15665 15197 14329>,
			<11634 11401 14083 15203 14731 14085>,
			<11518 11375 13616 15089 14601 14306>,
			<11420 11306 13212 15034 14537 14574>,
			<11311 11244 12950 15014 14858 14557>,
			<11253 11212 12850 15177 15227 14592>,
			<11299 11270 13211 15267 14593 13918>,
			<11417 11291 13132 14893 14279 13505>,
			<11439 11318 12957 14088 14156 14378>,
			<11566 11353 12989 14161 14478 15994>,
			<11894 11449 13036 14577 14971 16403>,
			<11849 11524 13209 14529 16733 15733>,
			<11350 11402 13261 16268 17415 15945>,
			<10639 11324 13386 16900 16906 18342>,
			<10238 11050 13734 16834 17734 18217>,
			<10238 11050 13734 16834 17734 18217>,
			<10238 11050 13734 16834 17734 18217>;
	};

	qcom,pc-temp-y6-lut {
		qcom,lut-col-legend = <(-10) 0 10 25 40 50>;
		qcom,lut-row-legend = <10000 9800 9600 9400 9200 9000>,
			<8800 8600 8400 8200 8000 7800>,
			<7600 7400 7200 7000 6800 6600>,
			<6400 6200 6000 5800 5600 5400>,
			<5200 5000 4800 4600 4400 4200>,
			<4000 3800 3600 3400 3200 3000>,
			<2800 2600 2400 2200 2000 1800>,
			<1600 1400 1200 1000 900 800>,
			<700 600 500 400 300 200>,
			<100 0>;
		qcom,lut-data = <6466 5643 5251 5059 5011 5000>,
			<6585 5654 5251 5059 5011 5000>,
			<6658 5660 5251 5059 5011 5000>,
			<6695 5663 5251 5060 5012 5001>,
			<6709 5665 5251 5061 5013 5002>,
			<6711 5665 5251 5062 5014 5003>,
			<6679 5662 5252 5064 5015 5004>,
			<6626 5657 5253 5066 5017 5005>,
			<6622 5656 5255 5068 5019 5006>,
			<6676 5662 5258 5071 5021 5008>,
			<6716 5670 5263 5074 5023 5010>,
			<6660 5703 5281 5085 5028 5012>,
			<6540 5748 5305 5096 5035 5014>,
			<6450 5744 5306 5098 5037 5016>,
			<6371 5651 5287 5095 5038 5020>,
			<6328 5581 5274 5093 5039 5023>,
			<6337 5586 5280 5106 5043 5026>,
			<6354 5597 5288 5124 5049 5030>,
			<6357 5598 5286 5128 5056 5034>,
			<6329 5584 5265 5126 5065 5042>,
			<6288 5567 5241 5123 5070 5046>,
			<6224 5552 5224 5101 5053 5033>,
			<6147 5536 5211 5068 5024 5012>,
			<6140 5524 5206 5058 5015 5005>,
			<6293 5516 5204 5056 5012 5003>,
			<6481 5506 5203 5055 5012 5002>,
			<6603 5470 5205 5056 5012 5003>,
			<6708 5417 5208 5058 5014 5004>,
			<6791 5407 5210 5061 5016 5006>,
			<6857 5457 5211 5065 5020 5009>,
			<6913 5524 5211 5069 5024 5012>,
			<6964 5585 5205 5074 5029 5016>,
			<7009 5649 5195 5077 5034 5020>,
			<7054 5702 5196 5078 5035 5021>,
			<7097 5742 5214 5077 5035 5020>,
			<7140 5781 5235 5076 5033 5019>,
			<7187 5824 5252 5074 5028 5013>,
			<7236 5868 5268 5071 5019 5006>,
			<7281 5915 5281 5071 5017 5005>,
			<7320 5965 5293 5072 5019 5006>,
			<7359 6019 5304 5073 5020 5007>,
			<7404 6081 5316 5074 5020 5007>,
			<7454 6151 5329 5075 5020 5007>,
			<7524 6228 5347 5077 5019 5005>,
			<7613 6317 5363 5078 5019 5005>,
			<7628 6323 5320 5075 5023 5010>,
			<7537 6299 5335 5080 5026 5012>,
			<7654 6389 5356 5087 5030 5016>,
			<7782 6490 5390 5097 5035 5024>,
			<7917 6597 5424 5099 5034 5020>,
			<8037 6696 5431 5088 5028 5012>,
			<8276 6837 5461 5105 5033 5015>,
			<8887 7108 5533 5124 5040 5026>,
			<9661 7547 5632 5158 5065 5046>,
			<9661 7547 5632 5158 5065 5046>,
			<9661 7547 5632 5158 5065 5046>;
	};

};
